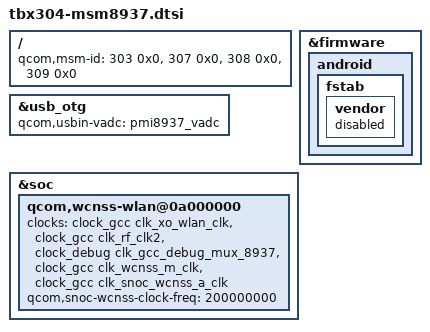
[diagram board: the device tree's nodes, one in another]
/ {
	qcom,msm-id = <303 0x0>, <307 0x0>, <308 0x0>, <309 0x0>;
};

&firmware {
	android {
		fstab {
			vendor {
				status = "disabled";
			};
		};
	};
};

&usb_otg{
	qcom,usbin-vadc = <&pmi8937_vadc>;
};

&soc {
	qcom,wcnss-wlan@0a000000 {
		clock-names = "xo", "rf_clk", "measure", "wcnss_debug","snoc_wcnss";
		clocks = <&clock_gcc clk_xo_wlan_clk>,
			 <&clock_gcc clk_rf_clk2>,
			 <&clock_debug clk_gcc_debug_mux_8937>,
			 <&clock_gcc clk_wcnss_m_clk>,
			 <&clock_gcc clk_snoc_wcnss_a_clk>;
		qcom,snoc-wcnss-clock-freq = <200000000>;
	};
};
